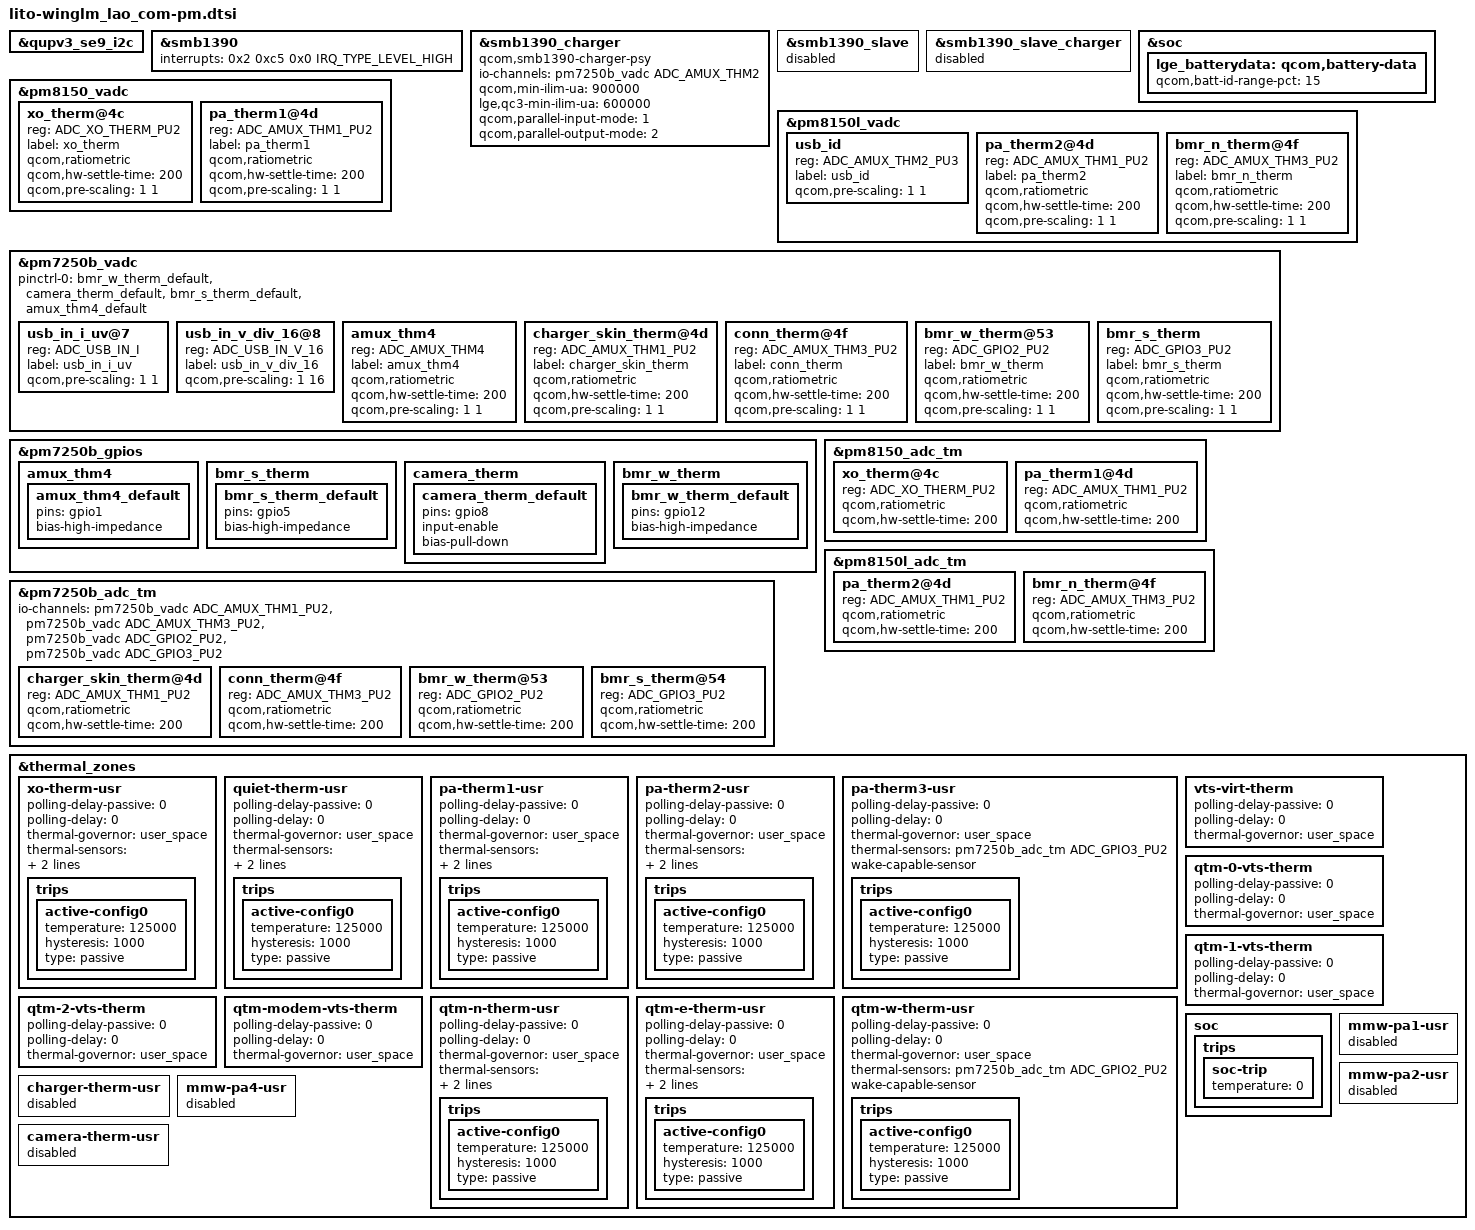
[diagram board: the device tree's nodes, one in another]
// SPDX-License-Identifier: GPL-2.0-only
/*
 * Copyright (c) 2018-2019, The Linux Foundation. All rights reserved.
 */

#include "../lito-winglm_common/lito-winglm_common-pm.dtsi"

&qupv3_se9_i2c {
	status = "ok";
	#include "../../../qcom/smb1390.dtsi"
};

&smb1390 {
	/delete-property/ interrupts;
	interrupts = <0x2 0xc5 0x0 IRQ_TYPE_LEVEL_HIGH>;
	status = "ok";
};

&smb1390_charger {
	compatible = "qcom,smb1390-charger-psy";
	io-channels = <&pm7250b_vadc ADC_AMUX_THM2>;
	qcom,min-ilim-ua = <900000>;
	lge,qc3-min-ilim-ua = <600000>;
	io-channel-names = "cp_die_temp";
	qcom,parallel-input-mode = <1>; /* USBIN */
	qcom,parallel-output-mode = <2>; /* VBAT */
	status = "ok";
};

&smb1390_slave {
	status = "disabled";
};

&smb1390_slave_charger {
	status = "disabled";
};

&soc {
    lge_batterydata: qcom,battery-data {
        qcom,batt-id-range-pct = <15>;
        #include "../../battery_profile/LGE_BLT52_ATL_4000mAh.dtsi"
    };
};

&pm8150_vadc {
	xo_therm@4c {
		reg = <ADC_XO_THERM_PU2>;
		label = "xo_therm";
		qcom,ratiometric;
		qcom,hw-settle-time = <200>;
		qcom,pre-scaling = <1 1>;
	};

	pa_therm1@4d {
		reg = <ADC_AMUX_THM1_PU2>;
		label = "pa_therm1";
		qcom,ratiometric;
		qcom,hw-settle-time = <200>;
		qcom,pre-scaling = <1 1>;
	};
};

&pm8150l_vadc {
    usb_id {
        reg = <ADC_AMUX_THM2_PU3>;
        label = "usb_id";
        qcom,pre-scaling = <1 1>;
    };

	pa_therm2@4d {
		reg = <ADC_AMUX_THM1_PU2>;
		label = "pa_therm2";
		qcom,ratiometric;
		qcom,hw-settle-time = <200>;
		qcom,pre-scaling = <1 1>;
	};

	/* qtm_n_therm */
	bmr_n_therm@4f {
		reg = <ADC_AMUX_THM3_PU2>;
		label = "bmr_n_therm";
		qcom,ratiometric;
		qcom,hw-settle-time = <200>;
		qcom,pre-scaling = <1 1>;
	};
};

&pm7250b_vadc {
    pinctrl-0 = <
        &bmr_w_therm_default
        &camera_therm_default
        &bmr_s_therm_default
        &amux_thm4_default
    >;

    usb_in_i_uv@7 {
        reg = <ADC_USB_IN_I>;
        label = "usb_in_i_uv";
        qcom,pre-scaling = <1 1>;
    };

    usb_in_v_div_16@8 {
        reg = <ADC_USB_IN_V_16>;
        label = "usb_in_v_div_16";
        qcom,pre-scaling = <1 16>;
    };

    amux_thm4 {
	reg = <ADC_AMUX_THM4>;
	label = "amux_thm4";
	qcom,ratiometric;
	qcom,hw-settle-time = <200>;
	qcom,pre-scaling = <1 1>;
    };

	/* quiet_therm */
	charger_skin_therm@4d {
		reg = <ADC_AMUX_THM1_PU2>;
		label = "charger_skin_therm";
		qcom,ratiometric;
		qcom,hw-settle-time = <200>;
		qcom,pre-scaling = <1 1>;
	};

	/* qtm_e_therm */
	conn_therm@4f {
		reg = <ADC_AMUX_THM3_PU2>;
		label = "conn_therm";
		qcom,ratiometric;
		qcom,hw-settle-time = <200>;
		qcom,pre-scaling = <1 1>;
	};

	/* qtm_w_therm */
	bmr_w_therm@53 {
		reg = <ADC_GPIO2_PU2>;
		label = "bmr_w_therm";
		qcom,ratiometric;
		qcom,hw-settle-time = <200>;
		qcom,pre-scaling = <1 1>;
	};

	/* pa_therm3 */
	bmr_s_therm {
		reg = <ADC_GPIO3_PU2>;
		label = "bmr_s_therm";
		qcom,ratiometric;
		qcom,hw-settle-time = <200>;
		qcom,pre-scaling = <1 1>;
	};
};

&pm7250b_gpios {
    amux_thm4 {
		amux_thm4_default: amux_thm4_default {
			pins = "gpio1";
			bias-high-impedance;
		};
    };
    bmr_s_therm {
        bmr_s_therm_default: bmr_s_therm_default {
            pins = "gpio5";
            bias-high-impedance;
        };
    };
    camera_therm {
		camera_therm_default: camera_therm_default {
			pins = "gpio8";
			input-enable;
			bias-pull-down;
		};
    };
    bmr_w_therm {
        bmr_w_therm_default: bmr_w_therm_default {
            pins = "gpio12";
            bias-high-impedance;
        };
    };
};

&pm8150_adc_tm {
	xo_therm@4c {
		reg = <ADC_XO_THERM_PU2>;
		qcom,ratiometric;
		qcom,hw-settle-time = <200>;
	};

	pa_therm1@4d {
		reg = <ADC_AMUX_THM1_PU2>;
		qcom,ratiometric;
		qcom,hw-settle-time = <200>;
	};
};

&pm8150l_adc_tm {
	pa_therm2@4d {
		reg = <ADC_AMUX_THM1_PU2>;
		qcom,ratiometric;
		qcom,hw-settle-time = <200>;
	};

	/* qtm_n_therm */
	bmr_n_therm@4f {
		reg = <ADC_AMUX_THM3_PU2>;
		qcom,ratiometric;
		qcom,hw-settle-time = <200>;
	};
};

&pm7250b_adc_tm {
	io-channels = <&pm7250b_vadc ADC_AMUX_THM1_PU2>,
			<&pm7250b_vadc ADC_AMUX_THM3_PU2>,
			<&pm7250b_vadc ADC_GPIO2_PU2>,
			<&pm7250b_vadc ADC_GPIO3_PU2>;

	/* quiet_therm */
	charger_skin_therm@4d {
		reg = <ADC_AMUX_THM1_PU2>;
		qcom,ratiometric;
		qcom,hw-settle-time = <200>;
	};

	/* qtm_e_therm */
	conn_therm@4f {
		reg = <ADC_AMUX_THM3_PU2>;
		qcom,ratiometric;
		qcom,hw-settle-time = <200>;
	};

	/* qtm_w_therm */
	bmr_w_therm@53 {
		reg = <ADC_GPIO2_PU2>;
		qcom,ratiometric;
		qcom,hw-settle-time = <200>;
	};

	/* pa_therm3 */
	bmr_s_therm@54 {
		reg = <ADC_GPIO3_PU2>;
		qcom,ratiometric;
		qcom,hw-settle-time = <200>;
	};

	/* Unused io-channel "&pm7250b_vadc ADC_GPIO4_PU2" and and their child node "camera_flash_therm" should be removed in main dtsi,
	   because maximum four ADC_TM channels can be added. */
};

&thermal_zones {
	xo-therm-usr {
		polling-delay-passive = <0>;
		polling-delay = <0>;
		thermal-governor = "user_space";
		thermal-sensors = <&pm8150_adc_tm ADC_XO_THERM_PU2>;
		wake-capable-sensor;
		trips {
			active-config0 {
				temperature = <125000>;
				hysteresis = <1000>;
				type = "passive";
			};
		};
	};

	quiet-therm-usr {
		polling-delay-passive = <0>;
		polling-delay = <0>;
		thermal-governor = "user_space";
		thermal-sensors = <&pm7250b_adc_tm ADC_AMUX_THM1_PU2>;
		wake-capable-sensor;
		trips {
			active-config0 {
				temperature = <125000>;
				hysteresis = <1000>;
				type = "passive";
			};
		};
	};

	pa-therm1-usr {
		polling-delay-passive = <0>;
		polling-delay = <0>;
		thermal-governor = "user_space";
		thermal-sensors = <&pm8150_adc_tm ADC_AMUX_THM1_PU2>;
		wake-capable-sensor;
		trips {
			active-config0 {
				temperature = <125000>;
				hysteresis = <1000>;
				type = "passive";
			};
		};
	};

	pa-therm2-usr {
		polling-delay-passive = <0>;
		polling-delay = <0>;
		thermal-governor = "user_space";
		thermal-sensors = <&pm8150l_adc_tm ADC_AMUX_THM1_PU2>;
		wake-capable-sensor;
		trips {
			active-config0 {
				temperature = <125000>;
				hysteresis = <1000>;
				type = "passive";
			};
		};
	};

	pa-therm3-usr {
		polling-delay-passive = <0>;
		polling-delay = <0>;
		thermal-governor = "user_space";
		thermal-sensors = <&pm7250b_adc_tm ADC_GPIO3_PU2>;
		wake-capable-sensor;
		trips {
		active-config0 {
			temperature = <125000>;
			hysteresis = <1000>;
			type = "passive";
		};
		};
	};

	vts-virt-therm {
		polling-delay-passive = <0>;
		polling-delay = <0>;
		thermal-governor = "user_space";
	};

	qtm-0-vts-therm {
		polling-delay-passive = <0>;
		polling-delay = <0>;
		thermal-governor = "user_space";
	};

	qtm-1-vts-therm {
		polling-delay-passive = <0>;
		polling-delay = <0>;
		thermal-governor = "user_space";
	};

	qtm-2-vts-therm {
		polling-delay-passive = <0>;
		polling-delay = <0>;
		thermal-governor = "user_space";
	};

	qtm-modem-vts-therm {
		polling-delay-passive = <0>;
		polling-delay = <0>;
		thermal-governor = "user_space";
	};

	qtm-n-therm-usr {
		polling-delay-passive = <0>;
		polling-delay = <0>;
		thermal-governor = "user_space";
		thermal-sensors = <&pm8150l_adc_tm ADC_AMUX_THM3_PU2>;
		wake-capable-sensor;
		trips {
			active-config0 {
				temperature = <125000>;
				hysteresis = <1000>;
				type = "passive";
			};
		};
	};

	qtm-e-therm-usr {
		polling-delay-passive = <0>;
		polling-delay = <0>;
		thermal-governor = "user_space";
		thermal-sensors = <&pm7250b_adc_tm ADC_AMUX_THM3_PU2>;
		wake-capable-sensor;
		trips {
			active-config0 {
				temperature = <125000>;
				hysteresis = <1000>;
				type = "passive";
			};
		};
	};

	qtm-w-therm-usr {
		polling-delay-passive = <0>;
		polling-delay = <0>;
		thermal-governor = "user_space";
		thermal-sensors = <&pm7250b_adc_tm ADC_GPIO2_PU2>;
		wake-capable-sensor;
		trips {
			active-config0 {
				temperature = <125000>;
				hysteresis = <1000>;
				type = "passive";
			};
		};
	};

	soc {
		trips {
			soc-trip {
				temperature = <0>;
			};
		};
	};

	charger-therm-usr {
		status = "disabled";
	};

	mmw-pa1-usr {
		status = "disabled";
	};

	mmw-pa2-usr {
		status = "disabled";
	};

	mmw-pa4-usr {
		status = "disabled";
	};

	camera-therm-usr {
		status = "disabled";
	};
};

